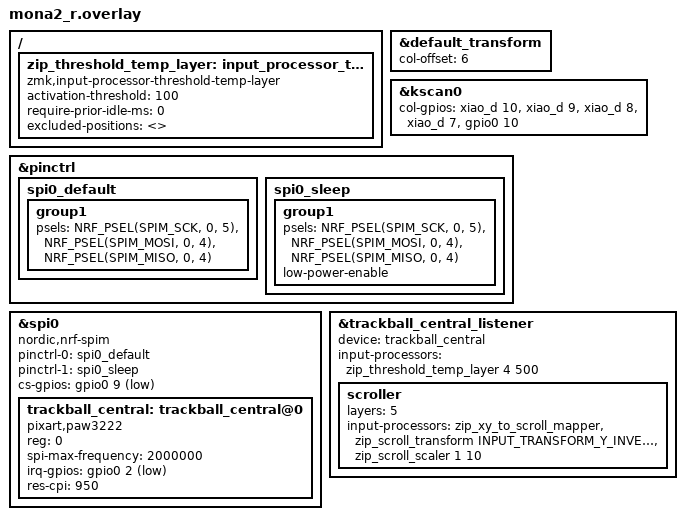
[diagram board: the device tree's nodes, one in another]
#include "mona2.dtsi"
#include <input/processors.dtsi>
#include <zephyr/dt-bindings/input/input-event-codes.h>

/ {
    // カスタム入力プロセッサー: 閾値付き一時レイヤー
    zip_threshold_temp_layer: input_processor_threshold_temp_layer {
        compatible = "zmk,input-processor-threshold-temp-layer";
        #input-processor-cells = <2>;
        activation-threshold = <100>;  // トラックボールを100ピクセル移動後にオートマウスレイヤーへ切り替え
        require-prior-idle-ms = <0>;
        excluded-positions = <>;
    };
};

&default_transform {
    col-offset = <6>;
};

&kscan0 {
        col-gpios
            = <&xiao_d 10 GPIO_ACTIVE_HIGH>
            , <&xiao_d 9 GPIO_ACTIVE_HIGH> 
            , <&xiao_d 8 GPIO_ACTIVE_HIGH> 
            , <&xiao_d 7 GPIO_ACTIVE_HIGH> 
            , <&gpio0 10 GPIO_ACTIVE_HIGH>
            ;
};


&pinctrl {
    spi0_default: spi0_default {    //通常時(SPI通信中)のピン構成
        group1 {
            psels = <NRF_PSEL(SPIM_SCK, 0, 5)>, //P0.05を指定(SCLK)
                <NRF_PSEL(SPIM_MOSI, 0, 4)>,    //P0.04を指定(SDIOだからMOSI,MISO両方の役割を担う)
                <NRF_PSEL(SPIM_MISO, 0, 4)>;
        };
    };

    spi0_sleep: spi0_sleep {    //スリープ時のピン構成(省電力)
        group1 {
            psels = <NRF_PSEL(SPIM_SCK, 0, 5)>,
                <NRF_PSEL(SPIM_MOSI, 0, 4)>,
                <NRF_PSEL(SPIM_MISO, 0, 4)>;
            low-power-enable;
        };
    };
};


&spi0 {
    status = "okay";
    compatible = "nordic,nrf-spim"; //マイコンがnRFシリーズ
    pinctrl-0 = <&spi0_default>;
    pinctrl-1 = <&spi0_sleep>;
    pinctrl-names = "default", "sleep";
    cs-gpios = <&gpio0 9 GPIO_ACTIVE_LOW>;  //P0.09を指定(CS)

    trackball_central: trackball_central@0 {
        status = "okay";
        compatible = "pixart,paw3222";  //トラボセンサ用のドライバとバインド
        reg = <0>;
        spi-max-frequency = <2000000>;
        irq-gpios = <&gpio0 2 (GPIO_ACTIVE_LOW | GPIO_PULL_UP)>; //P0.02を指定(MOTION)
        res-cpi = <950>;
    };
};


// Overrides for the input listener node
&trackball_central_listener {
    status = "okay";
    device = <&trackball_central>;

    // 通常のポインター移動 + オートマウスレイヤー（閾値付き）
    input-processors = <&zip_threshold_temp_layer 4 500>;  //オートマウスレイヤー（100ピクセル移動後、レイヤー4=MOUSE に500ms切り替え）
                                                           // ↑ 自動レイヤー切替が不要なら、この行をコメントアウトする

    scroller {
        layers = <5>;   // レイヤー5 = SCROLL
        input-processors = <&zip_xy_to_scroll_mapper>,                         //スクロールモードに変更
                           <&zip_scroll_transform INPUT_TRANSFORM_Y_INVERT>,   //スクロールのY軸反転
                           <&zip_scroll_scaler 1 10>;                          //スクロール量を1/10倍
    };

};
